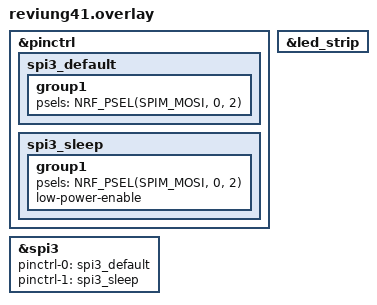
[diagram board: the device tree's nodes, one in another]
#include <dt-bindings/led/led.h>

&pinctrl {
    spi3_default: spi3_default {
        group1 {
            psels = <NRF_PSEL(SPIM_MOSI, 0, 2)>; // Map to P0.02 (physical pin A1 on the Pro Micro footprint)
        };
    };

    spi3_sleep: spi3_sleep {
        group1 {
            psels = <NRF_PSEL(SPIM_MOSI, 0, 2)>;
            low-power-enable;
        };
    };
};

&spi3 {
    pinctrl-0 = <&spi3_default>;
    pinctrl-1 = <&spi3_sleep>;
    pinctrl-names = "default", "sleep";
};

&led_strip {
    status = "okay";
};
